# ESP32-P4-LP register map
Vendor: ESPRESSIF SYSTEMS (SHANGHAI) CO., LTD.; Series: ESP32 P-Series; File version: 3
CPU: RV32IMAC r0p0, little endian, no MPU, no FPU, 0 interrupt priority bits
Address unit: 32 bits
Registers are 32-bit, read-write, reset 0x0 unless marked. A register's access mark holds for its fields unless they carry their own. Offsets are from the block's base; [hi:lo] are bit positions; {n}, {i} and the like mark numbered series.

## LP_ANA_PERI — LP_ANA_PERI Peripheral
Base 0x50113000
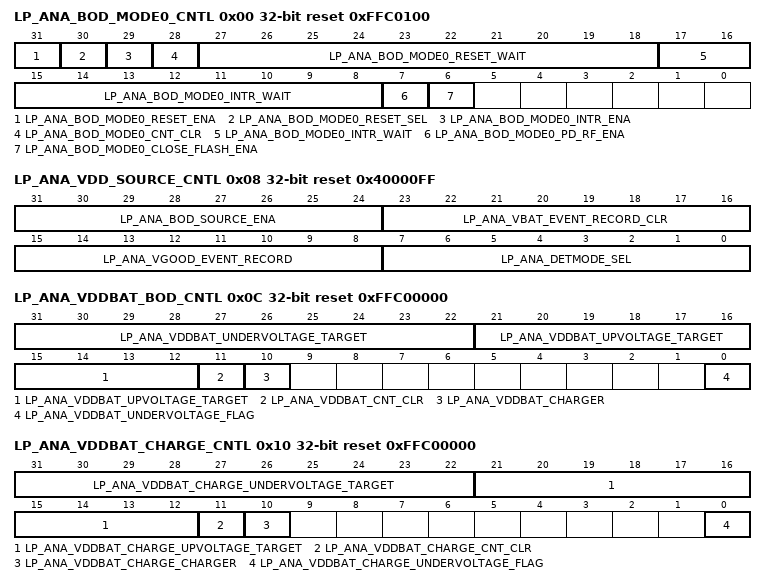
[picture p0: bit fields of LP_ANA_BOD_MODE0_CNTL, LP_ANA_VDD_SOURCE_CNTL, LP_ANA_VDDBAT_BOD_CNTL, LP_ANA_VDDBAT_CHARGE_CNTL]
0x00 LP_ANA_BOD_MODE0_CNTL reset 0xFFC0100 — need_des
  [31] LP_ANA_BOD_MODE0_RESET_ENA — need_des
  [30] LP_ANA_BOD_MODE0_RESET_SEL — need_des
  [29] LP_ANA_BOD_MODE0_INTR_ENA — need_des
  [28] LP_ANA_BOD_MODE0_CNT_CLR — need_des
  [27:18] LP_ANA_BOD_MODE0_RESET_WAIT — need_des
  [17:8] LP_ANA_BOD_MODE0_INTR_WAIT — need_des
  [7] LP_ANA_BOD_MODE0_PD_RF_ENA — need_des
  [6] LP_ANA_BOD_MODE0_CLOSE_FLASH_ENA — need_des
0x04 LP_ANA_BOD_MODE1_CNTL — need_des
  [31] LP_ANA_BOD_MODE1_RESET_ENA
0x08 LP_ANA_VDD_SOURCE_CNTL access per field reset 0x40000FF — need_des
  [31:24] LP_ANA_BOD_SOURCE_ENA rw — need_des
  [23:16] LP_ANA_VBAT_EVENT_RECORD_CLR wo — need_des
  [15:8] LP_ANA_VGOOD_EVENT_RECORD ro — need_des
  [7:0] LP_ANA_DETMODE_SEL rw — need_des
0x0C LP_ANA_VDDBAT_BOD_CNTL access per field reset 0xFFC00000 — need_des
  [31:22] LP_ANA_VDDBAT_UNDERVOLTAGE_TARGET rw — need_des
  [21:12] LP_ANA_VDDBAT_UPVOLTAGE_TARGET rw — need_des
  [11] LP_ANA_VDDBAT_CNT_CLR rw — need_des
  [10] LP_ANA_VDDBAT_CHARGER rw — need_des
  [0] LP_ANA_VDDBAT_UNDERVOLTAGE_FLAG ro — need_des
0x10 LP_ANA_VDDBAT_CHARGE_CNTL access per field reset 0xFFC00000 — need_des
  [31:22] LP_ANA_VDDBAT_CHARGE_UNDERVOLTAGE_TARGET rw — need_des
  [21:12] LP_ANA_VDDBAT_CHARGE_UPVOLTAGE_TARGET rw — need_des
  [11] LP_ANA_VDDBAT_CHARGE_CNT_CLR rw — need_des
  [10] LP_ANA_VDDBAT_CHARGE_CHARGER rw — need_des
  [0] LP_ANA_VDDBAT_CHARGE_UNDERVOLTAGE_FLAG ro — need_des
0x14 LP_ANA_CK_GLITCH_CNTL — need_des
  [31] LP_ANA_CK_GLITCH_RESET_ENA
0x18 LP_ANA_PG_GLITCH_CNTL — need_des
  [31] LP_ANA_POWER_GLITCH_RESET_ENA
0x1C LP_ANA_FIB_ENABLE reset 0xFFFFFFFF — need_des
  [31:0] LP_ANA_ANA_FIB_ENA
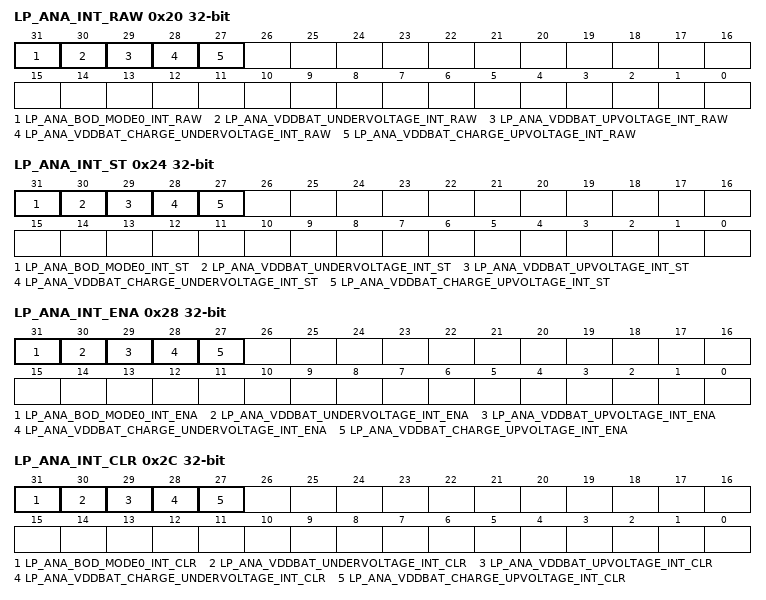
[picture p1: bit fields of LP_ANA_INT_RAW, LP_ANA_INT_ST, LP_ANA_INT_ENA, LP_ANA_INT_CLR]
0x20 LP_ANA_INT_RAW — need_des
  [31] LP_ANA_BOD_MODE0_INT_RAW — need_des
  [30] LP_ANA_VDDBAT_UNDERVOLTAGE_INT_RAW — need_des
  [29] LP_ANA_VDDBAT_UPVOLTAGE_INT_RAW — need_des
  [28] LP_ANA_VDDBAT_CHARGE_UNDERVOLTAGE_INT_RAW — need_des
  [27] LP_ANA_VDDBAT_CHARGE_UPVOLTAGE_INT_RAW — need_des
0x24 LP_ANA_INT_ST ro — need_des
  [31] LP_ANA_BOD_MODE0_INT_ST — need_des
  [30] LP_ANA_VDDBAT_UNDERVOLTAGE_INT_ST — need_des
  [29] LP_ANA_VDDBAT_UPVOLTAGE_INT_ST — need_des
  [28] LP_ANA_VDDBAT_CHARGE_UNDERVOLTAGE_INT_ST — need_des
  [27] LP_ANA_VDDBAT_CHARGE_UPVOLTAGE_INT_ST — need_des
0x28 LP_ANA_INT_ENA — need_des
  [31] LP_ANA_BOD_MODE0_INT_ENA — need_des
  [30] LP_ANA_VDDBAT_UNDERVOLTAGE_INT_ENA — need_des
  [29] LP_ANA_VDDBAT_UPVOLTAGE_INT_ENA — need_des
  [28] LP_ANA_VDDBAT_CHARGE_UNDERVOLTAGE_INT_ENA — need_des
  [27] LP_ANA_VDDBAT_CHARGE_UPVOLTAGE_INT_ENA — need_des
0x2C LP_ANA_INT_CLR wo — need_des
  [31] LP_ANA_BOD_MODE0_INT_CLR — need_des
  [30] LP_ANA_VDDBAT_UNDERVOLTAGE_INT_CLR — need_des
  [29] LP_ANA_VDDBAT_UPVOLTAGE_INT_CLR — need_des
  [28] LP_ANA_VDDBAT_CHARGE_UNDERVOLTAGE_INT_CLR — need_des
  [27] LP_ANA_VDDBAT_CHARGE_UPVOLTAGE_INT_CLR — need_des
0x30 LP_ANA_LP_INT_RAW — need_des
  [31] LP_ANA_BOD_MODE0_LP_INT_RAW
0x34 LP_ANA_LP_INT_ST ro — need_des
  [31] LP_ANA_BOD_MODE0_LP_INT_ST
0x38 LP_ANA_LP_INT_ENA — need_des
  [31] LP_ANA_BOD_MODE0_LP_INT_ENA
0x3C LP_ANA_LP_INT_CLR wo — need_des
  [31] LP_ANA_BOD_MODE0_LP_INT_CLR
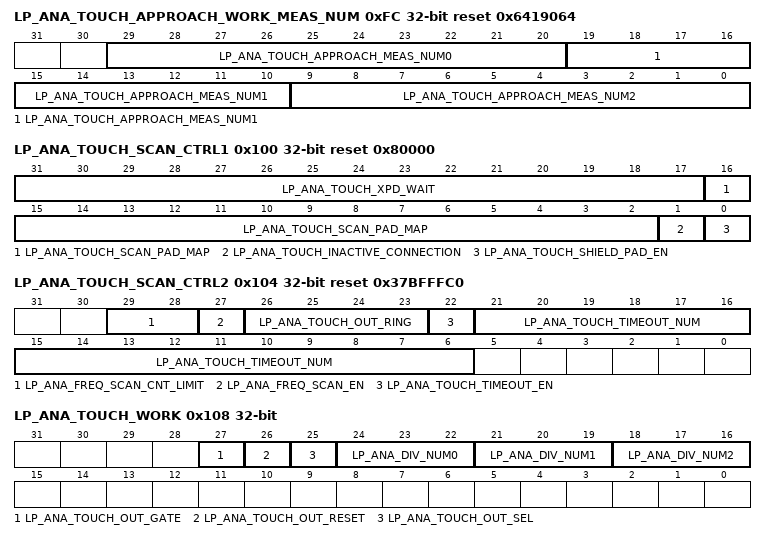
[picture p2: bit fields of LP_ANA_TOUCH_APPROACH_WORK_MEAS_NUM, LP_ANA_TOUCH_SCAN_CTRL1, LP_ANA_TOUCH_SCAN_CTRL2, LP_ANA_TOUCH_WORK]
0xFC LP_ANA_TOUCH_APPROACH_WORK_MEAS_NUM reset 0x6419064 — need_des
  [29:20] LP_ANA_TOUCH_APPROACH_MEAS_NUM0 — need_des
  [19:10] LP_ANA_TOUCH_APPROACH_MEAS_NUM1 — need_des
  [9:0] LP_ANA_TOUCH_APPROACH_MEAS_NUM2 — need_des
0x100 LP_ANA_TOUCH_SCAN_CTRL1 reset 0x80000 — need_des
  [31:17] LP_ANA_TOUCH_XPD_WAIT — need_des
  [16:2] LP_ANA_TOUCH_SCAN_PAD_MAP — need_des
  [1] LP_ANA_TOUCH_INACTIVE_CONNECTION — need_des
  [0] LP_ANA_TOUCH_SHIELD_PAD_EN — need_des
0x104 LP_ANA_TOUCH_SCAN_CTRL2 reset 0x37BFFFC0 — need_des
  [29:28] LP_ANA_FREQ_SCAN_CNT_LIMIT — need_des
  [27] LP_ANA_FREQ_SCAN_EN — need_des
  [26:23] LP_ANA_TOUCH_OUT_RING — need_des
  [22] LP_ANA_TOUCH_TIMEOUT_EN — need_des
  [21:6] LP_ANA_TOUCH_TIMEOUT_NUM — need_des
0x108 LP_ANA_TOUCH_WORK access per field — need_des
  [27] LP_ANA_TOUCH_OUT_GATE rw — need_des
  [26] LP_ANA_TOUCH_OUT_RESET wo — need_des
  [25] LP_ANA_TOUCH_OUT_SEL rw — need_des
  [24:22] LP_ANA_DIV_NUM0 rw — need_des
  [21:19] LP_ANA_DIV_NUM1 rw — need_des
  [18:16] LP_ANA_DIV_NUM2 rw — need_des
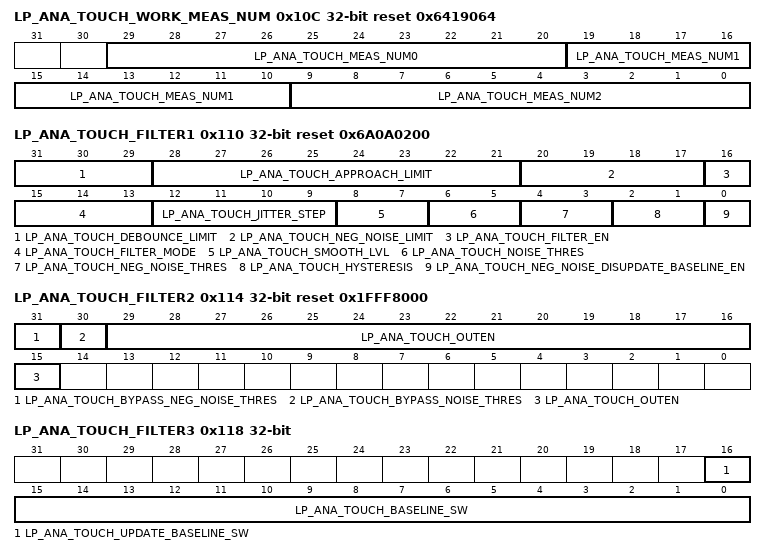
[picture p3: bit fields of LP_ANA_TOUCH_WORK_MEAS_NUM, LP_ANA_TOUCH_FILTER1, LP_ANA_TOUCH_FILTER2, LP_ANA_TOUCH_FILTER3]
0x10C LP_ANA_TOUCH_WORK_MEAS_NUM reset 0x6419064 — need_des
  [29:20] LP_ANA_TOUCH_MEAS_NUM0 — need_des
  [19:10] LP_ANA_TOUCH_MEAS_NUM1 — need_des
  [9:0] LP_ANA_TOUCH_MEAS_NUM2 — need_des
0x110 LP_ANA_TOUCH_FILTER1 reset 0x6A0A0200 — need_des
  [31:29] LP_ANA_TOUCH_DEBOUNCE_LIMIT — need_des
  [28:21] LP_ANA_TOUCH_APPROACH_LIMIT — need_des
  [20:17] LP_ANA_TOUCH_NEG_NOISE_LIMIT — need_des
  [16] LP_ANA_TOUCH_FILTER_EN — need_des
  [15:13] LP_ANA_TOUCH_FILTER_MODE — need_des
  [12:9] LP_ANA_TOUCH_JITTER_STEP — need_des
  [8:7] LP_ANA_TOUCH_SMOOTH_LVL — need_des
  [6:5] LP_ANA_TOUCH_NOISE_THRES — need_des
  [4:3] LP_ANA_TOUCH_NEG_NOISE_THRES — need_des
  [2:1] LP_ANA_TOUCH_HYSTERESIS — need_des
  [0] LP_ANA_TOUCH_NEG_NOISE_DISUPDATE_BASELINE_EN — Reserved
0x114 LP_ANA_TOUCH_FILTER2 reset 0x1FFF8000 — need_des
  [31] LP_ANA_TOUCH_BYPASS_NEG_NOISE_THRES — need_des
  [30] LP_ANA_TOUCH_BYPASS_NOISE_THRES — need_des
  [29:15] LP_ANA_TOUCH_OUTEN — need_des
0x118 LP_ANA_TOUCH_FILTER3 access per field — need_des
  [16] LP_ANA_TOUCH_UPDATE_BASELINE_SW wo — need_des
  [15:0] LP_ANA_TOUCH_BASELINE_SW rw — need_des
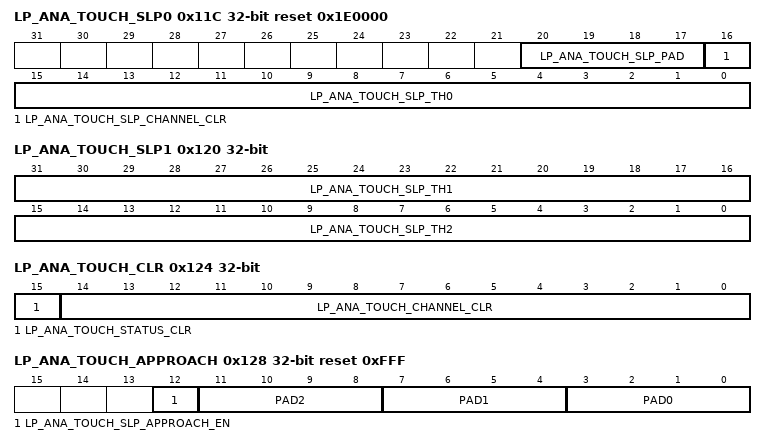
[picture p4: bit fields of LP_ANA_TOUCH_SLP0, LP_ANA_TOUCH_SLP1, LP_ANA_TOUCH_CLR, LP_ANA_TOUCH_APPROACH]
0x11C LP_ANA_TOUCH_SLP0 access per field reset 0x1E0000 — need_des
  [20:17] LP_ANA_TOUCH_SLP_PAD rw — need_des
  [16] LP_ANA_TOUCH_SLP_CHANNEL_CLR wo — need_des
  [15:0] LP_ANA_TOUCH_SLP_TH0 rw — need_des
0x120 LP_ANA_TOUCH_SLP1 — need_des
  [31:16] LP_ANA_TOUCH_SLP_TH1 — need_des
  [15:0] LP_ANA_TOUCH_SLP_TH2 — need_des
0x124 LP_ANA_TOUCH_CLR wo — need_des
  [15] LP_ANA_TOUCH_STATUS_CLR — need_des
  [14:0] LP_ANA_TOUCH_CHANNEL_CLR — need_des
0x128 LP_ANA_TOUCH_APPROACH reset 0xFFF — need_des
  [12] LP_ANA_TOUCH_SLP_APPROACH_EN — need_des
  [11:8] PAD2 — need_des
  [7:4] PAD1 — need_des
  [3:0] PAD0 — need_des
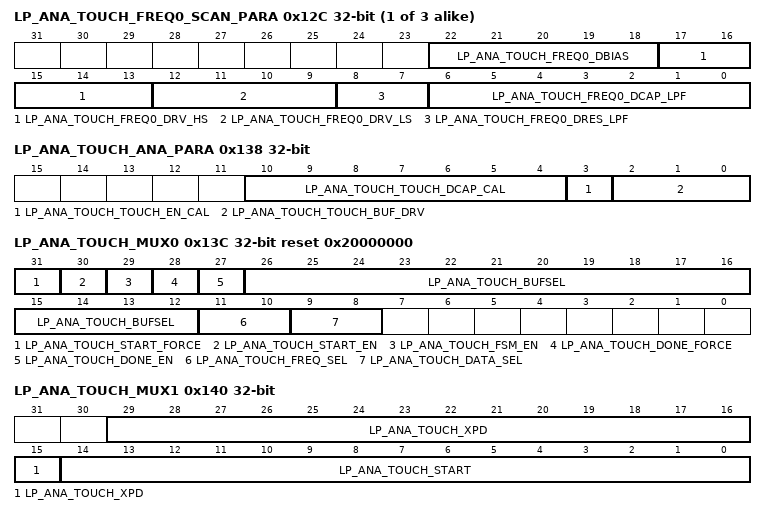
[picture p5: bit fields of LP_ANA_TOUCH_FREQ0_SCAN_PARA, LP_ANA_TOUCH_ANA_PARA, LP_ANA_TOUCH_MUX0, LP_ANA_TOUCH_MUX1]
{0x12C+4i} LP_ANA_TOUCH_FREQ{i}_SCAN_PARA (i=0..2) — need_des
  [22:18] LP_ANA_TOUCH_FREQ{i}_DBIAS — need_des
  [17:13] LP_ANA_TOUCH_FREQ{i}_DRV_HS — need_des
  [12:9] LP_ANA_TOUCH_FREQ{i}_DRV_LS — need_des
  [8:7] LP_ANA_TOUCH_FREQ{i}_DRES_LPF — need_des
  [6:0] LP_ANA_TOUCH_FREQ{i}_DCAP_LPF — need_des
0x138 LP_ANA_TOUCH_ANA_PARA — need_des
  [10:4] LP_ANA_TOUCH_TOUCH_DCAP_CAL — need_des
  [3] LP_ANA_TOUCH_TOUCH_EN_CAL — need_des
  [2:0] LP_ANA_TOUCH_TOUCH_BUF_DRV — need_des
0x13C LP_ANA_TOUCH_MUX0 reset 0x20000000 — need_des
  [31] LP_ANA_TOUCH_START_FORCE — need_des
  [30] LP_ANA_TOUCH_START_EN — need_des
  [29] LP_ANA_TOUCH_FSM_EN — need_des
  [28] LP_ANA_TOUCH_DONE_FORCE — need_des
  [27] LP_ANA_TOUCH_DONE_EN — need_des
  [26:12] LP_ANA_TOUCH_BUFSEL — need_des
  [11:10] LP_ANA_TOUCH_FREQ_SEL — need_des
  [9:8] LP_ANA_TOUCH_DATA_SEL — need_des
0x140 LP_ANA_TOUCH_MUX1 — need_des
  [29:15] LP_ANA_TOUCH_XPD — need_des
  [14:0] LP_ANA_TOUCH_START — need_des
{0x144+0xC*i} LP_ANA_TOUCH_PAD{i}_TH0 (i=0..14) — need_des
  [31:16] LP_ANA_TOUCH_PAD{i}_TH0 — Reserved
{0x148+0xC*i} LP_ANA_TOUCH_PAD{i}_TH1 (i=0..14) — need_des
  [31:16] LP_ANA_TOUCH_PAD{i}_TH1 — Reserved
{0x14C+0xC*i} LP_ANA_TOUCH_PAD{i}_TH2 (i=0..14) — need_des
  [31:16] LP_ANA_TOUCH_PAD{i}_TH2 — Reserved
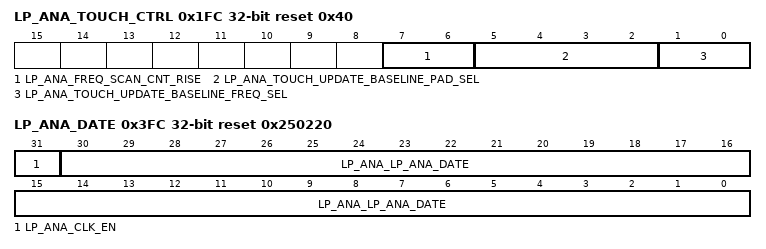
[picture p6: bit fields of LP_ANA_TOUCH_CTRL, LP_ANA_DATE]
0x1FC LP_ANA_TOUCH_CTRL reset 0x40 — Touch Control Register
  [7:6] LP_ANA_FREQ_SCAN_CNT_RISE — Configure the number of hit frequency points that need to be determined for touch in frequency hopping mode.
  [5:2] LP_ANA_TOUCH_UPDATE_BASELINE_PAD_SEL — Configure the channel for software to update the baseline.
  [1:0] LP_ANA_TOUCH_UPDATE_BASELINE_FREQ_SEL — Configure the frequency point for software to update the baseline
0x3FC LP_ANA_DATE reset 0x250220 — need_des
  [31] LP_ANA_CLK_EN — need_des
  [30:0] LP_ANA_LP_ANA_DATE — need_des
